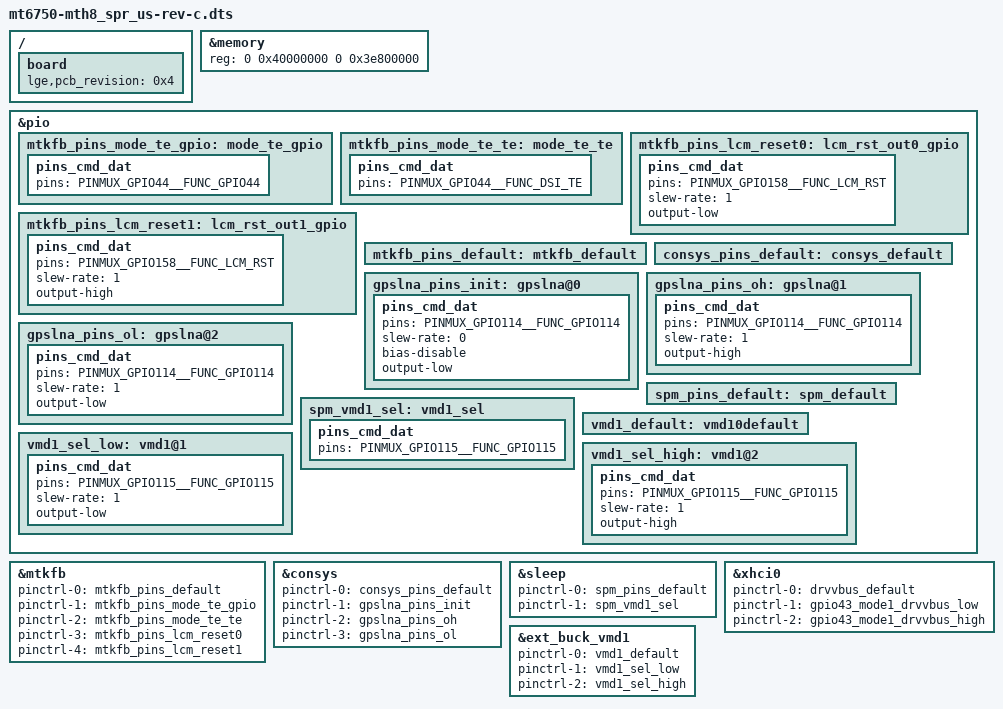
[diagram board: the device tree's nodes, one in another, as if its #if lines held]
#include <generated/autoconf.h>
/dts-v1/;

#ifdef CONFIG_MTK_DTBO_FEATURE
/plugin/;
#include <dt-bindings/mmc/mt6755-msdc.h>
#include "../../mt6755-pinfunc.h"
#else
#include "../../mt6755.dts"
#endif

#include "mt6750-mth8_spr_us-cust.dtsi"
#include "mt6750-mth8_spr_us-power.dtsi"
#include "mt6750-mth8_spr_us-panel.dtsi"
#include "mt6750-mth8_spr_us-touch.dtsi"
#include "mt6750-mth8_spr_us-sensor.dtsi"
#include "mt6750-mth8_spr_us-misc.dtsi"
#include "mt6750-mth8_spr_us-sound.dtsi"
/* #include "mt6750-mth8_spr_us-nfc.dtsi" */
#include "mt6750-mth8_spr_us-common.dtsi"
#include "mt6750-mth8_spr_us-usb.dtsi"
#include "mt6750-mth8_spr_us-camera.dtsi"

/ {
	board {
		/*
		   typedef enum {
		   HW_REV_0 = 0,
		   HW_REV_0_1,
		   HW_REV_A,
		   HW_REV_B,
		   HW_REV_C,
		   HW_REV_1_0,
		   HW_REV_1_1,
		   HW_REV_MAX
		   } rev_type;
		 */
		lge,pcb_revision = <0x4>; // rev_c
	};
};

&memory {
	device_type = "memory";
	reg = <0 0x40000000 0 0x3e800000>;
};

/* DISPSYS GPIO standardization */
&pio {

	mtkfb_pins_mode_te_gpio: mode_te_gpio {
		pins_cmd_dat {
			pins = <PINMUX_GPIO44__FUNC_GPIO44>;
		};
	};

	mtkfb_pins_mode_te_te: mode_te_te {
		pins_cmd_dat {
			pins = <PINMUX_GPIO44__FUNC_DSI_TE>;
		};
	};

	mtkfb_pins_lcm_reset0: lcm_rst_out0_gpio {
		pins_cmd_dat {
			pins = <PINMUX_GPIO158__FUNC_LCM_RST>;
			slew-rate = <1>;
			output-low;
		};
	};

	mtkfb_pins_lcm_reset1: lcm_rst_out1_gpio {
		pins_cmd_dat {
			pins = <PINMUX_GPIO158__FUNC_LCM_RST>;
			slew-rate = <1>;
			output-high;
		};
	};

	/*mtkfb_pins_lcd_bias_enp0: lcd_bias_enp0_gpio {
		pins_cmd_dat {
			pins = <PINMUX_GPIO12__FUNC_GPIO12>;
			slew-rate = <1>;
			output-low;
		};
	};

	mtkfb_pins_lcd_bias_enp1: lcd_bias_enp1_gpio {
		pins_cmd_dat {
			pins = <PINMUX_GPIO12__FUNC_GPIO12>;
			slew-rate = <1>;
			output-high;
		};
	};*/

	mtkfb_pins_default: mtkfb_default {
	};
};

&mtkfb {
	pinctrl-names = "default", "mode_te_gpio", "mode_te_te", "lcm_rst_out0_gpio",
	"lcm_rst_out1_gpio", "lcd_bias_enp0_gpio", "lcd_bias_enp1_gpio";
	pinctrl-0 = <&mtkfb_pins_default>;
	pinctrl-1 = <&mtkfb_pins_mode_te_gpio>;
	pinctrl-2 = <&mtkfb_pins_mode_te_te>;
	pinctrl-3 = <&mtkfb_pins_lcm_reset0>;
	pinctrl-4 = <&mtkfb_pins_lcm_reset1>;
	//pinctrl-5 = <&mtkfb_pins_lcd_bias_enp0>;
	//pinctrl-6 = <&mtkfb_pins_lcd_bias_enp1>;
	status = "okay";
};/* DISPSYS GPIO standardization end */

/* CONSYS GPIO standardization */
&pio {
	consys_pins_default: consys_default {
	};

	gpslna_pins_init: gpslna@0 {
		pins_cmd_dat {
			pins = <PINMUX_GPIO114__FUNC_GPIO114>;
			slew-rate = <0>;
			bias-disable;
			output-low;
		};
	};

	gpslna_pins_oh: gpslna@1 {
		pins_cmd_dat {
			pins = <PINMUX_GPIO114__FUNC_GPIO114>;
			slew-rate = <1>;
			output-high;
		};
	};

	gpslna_pins_ol: gpslna@2 {
		pins_cmd_dat {
			pins = <PINMUX_GPIO114__FUNC_GPIO114>;
			slew-rate = <1>;
			output-low;
		};
	};
};

&consys {
	pinctrl-names = "default", "gps_lna_state_init", "gps_lna_state_oh", "gps_lna_state_ol";
	pinctrl-0 = <&consys_pins_default>;
	pinctrl-1 = <&gpslna_pins_init>;
	pinctrl-2 = <&gpslna_pins_oh>;
	pinctrl-3 = <&gpslna_pins_ol>;
	status = "okay";
};
/* CONSYS end */

/* SPM GPIO standardization */
&pio {
	spm_pins_default: spm_default {
	};

	spm_vmd1_sel: vmd1_sel {
		pins_cmd_dat {
			pins = <PINMUX_GPIO115__FUNC_GPIO115>;
		};
	};

};

&sleep {
	pinctrl-names = "default", "vmd1_sel";
	pinctrl-0 = <&spm_pins_default>;
	pinctrl-1 = <&spm_vmd1_sel>;
	status = "okay";
};
/* SPM end */

&xhci0 {
	pinctrl-names = "drvvbus_default", "drvvbus_low", "drvvbus_high";
	pinctrl-0 = <&drvvbus_default>;
	pinctrl-1 = <&gpio43_mode1_drvvbus_low>;
	pinctrl-2 = <&gpio43_mode1_drvvbus_high>;
	status = "okay";
};

&ext_buck_vmd1 {
	pinctrl-names = "default", "vmd1_sel_low", "vmd1_sel_high";

	pinctrl-0 = <&vmd1_default>;
	pinctrl-1 = <&vmd1_sel_low>;
	pinctrl-2 = <&vmd1_sel_high>;
};

&pio {
	vmd1_default: vmd10default {
	};

	vmd1_sel_low: vmd1@1 {
		pins_cmd_dat {
			pins = <PINMUX_GPIO115__FUNC_GPIO115>;
			slew-rate = <1>;
			output-low;
		};
	};

	vmd1_sel_high: vmd1@2 {
		pins_cmd_dat {
			pins = <PINMUX_GPIO115__FUNC_GPIO115>;
			slew-rate = <1>;
			output-high;
		};
	};
};

